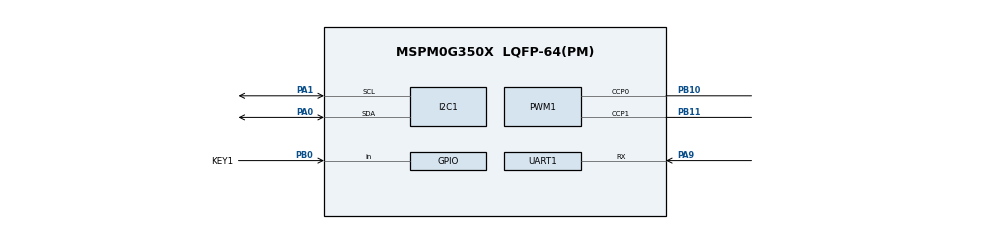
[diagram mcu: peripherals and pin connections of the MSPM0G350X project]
/**
 * @cliArgs --device "MSPM0G350X" --part "Default" --package "LQFP-64(PM)" --product "mspm0_sdk@2.04.00.06"
 * @versions {"tool":"1.21.1+3772"}
 */

/**
 * Import the modules used in this configuration.
 */
const GPIO   = scripting.addModule("/ti/driverlib/GPIO", {}, false);
const GPIO1  = GPIO.addInstance();
const GPIO2  = GPIO.addInstance();
const GPIO3  = GPIO.addInstance();
const GPIO4  = GPIO.addInstance();
const GPIO5  = GPIO.addInstance();
const GPIO6  = GPIO.addInstance();
const I2C    = scripting.addModule("/ti/driverlib/I2C", {}, false);
const I2C1   = I2C.addInstance();
const PWM    = scripting.addModule("/ti/driverlib/PWM", {}, false);
const PWM1   = PWM.addInstance();
const SYSCTL = scripting.addModule("/ti/driverlib/SYSCTL");
const TIMER  = scripting.addModule("/ti/driverlib/TIMER", {}, false);
const TIMER1 = TIMER.addInstance();
const UART   = scripting.addModule("/ti/driverlib/UART", {}, false);
const UART1  = UART.addInstance();

/**
 * Write custom configuration values to the imported modules.
 */
const divider7       = system.clockTree["PLL_PDIV"];
divider7.divideValue = 2;

const divider9       = system.clockTree["UDIV"];
divider9.divideValue = 2;

const multiplier2         = system.clockTree["PLL_QDIV"];
multiplier2.multiplyValue = 5;

const mux8       = system.clockTree["HSCLKMUX"];
mux8.inputSelect = "HSCLKMUX_SYSPLL2X";

GPIO1.$name                          = "TB";
GPIO1.associatedPins.create(4);
GPIO1.associatedPins[0].$name        = "AIN1";
GPIO1.associatedPins[0].assignedPort = "PORTB";
GPIO1.associatedPins[0].assignedPin  = "15";
GPIO1.associatedPins[1].$name        = "AIN2";
GPIO1.associatedPins[1].assignedPort = "PORTB";
GPIO1.associatedPins[1].assignedPin  = "13";
GPIO1.associatedPins[2].$name        = "BIN1";
GPIO1.associatedPins[2].assignedPort = "PORTB";
GPIO1.associatedPins[2].assignedPin  = "16";
GPIO1.associatedPins[3].$name        = "BIN2";
GPIO1.associatedPins[3].assignedPort = "PORTB";
GPIO1.associatedPins[3].assignedPin  = "12";

const Board = scripting.addModule("/ti/driverlib/Board", {}, false);

GPIO2.$name                          = "SG";
GPIO2.associatedPins.create(3);
GPIO2.associatedPins[0].$name        = "LED1";
GPIO2.associatedPins[0].assignedPort = "PORTB";
GPIO2.associatedPins[0].assignedPin  = "23";
GPIO2.associatedPins[1].$name        = "LED2";
GPIO2.associatedPins[1].assignedPin  = "21";
GPIO2.associatedPins[1].assignedPort = "PORTB";
GPIO2.associatedPins[2].$name        = "BUZZ";
GPIO2.associatedPins[2].assignedPort = "PORTB";
GPIO2.associatedPins[2].assignedPin  = "19";

GPIO3.$name                              = "KEY";
GPIO3.associatedPins.create(3);
GPIO3.associatedPins[0].$name            = "KEY2";
GPIO3.associatedPins[0].assignedPort     = "PORTB";
GPIO3.associatedPins[0].direction        = "INPUT";
GPIO3.associatedPins[0].internalResistor = "PULL_UP";
GPIO3.associatedPins[0].assignedPin      = "7";
GPIO3.associatedPins[1].$name            = "KEY3";
GPIO3.associatedPins[1].direction        = "INPUT";
GPIO3.associatedPins[1].internalResistor = "PULL_UP";
GPIO3.associatedPins[1].assignedPort     = "PORTB";
GPIO3.associatedPins[1].assignedPin      = "9";
GPIO3.associatedPins[2].$name            = "KEY1";
GPIO3.associatedPins[2].direction        = "INPUT";
GPIO3.associatedPins[2].internalResistor = "PULL_UP";
GPIO3.associatedPins[2].assignedPort     = "PORTB";
GPIO3.associatedPins[2].assignedPin      = "0";
GPIO3.associatedPins[2].pin.$assign      = "PB0";

GPIO4.$name                               = "EncoderA";
GPIO4.associatedPins.create(2);
GPIO4.associatedPins[0].$name             = "A_A";
GPIO4.associatedPins[0].direction         = "INPUT";
GPIO4.associatedPins[0].internalResistor  = "PULL_DOWN";
GPIO4.associatedPins[0].inputFilter       = "8_CYCLES";
GPIO4.associatedPins[0].interruptEn       = true;
GPIO4.associatedPins[0].interruptPriority = "0";
GPIO4.associatedPins[0].polarity          = "RISE";
GPIO4.associatedPins[0].assignedPort      = "PORTA";
GPIO4.associatedPins[0].assignedPin       = "26";
GPIO4.associatedPins[1].$name             = "A_B";
GPIO4.associatedPins[1].direction         = "INPUT";
GPIO4.associatedPins[1].internalResistor  = "PULL_DOWN";
GPIO4.associatedPins[1].inputFilter       = "8_CYCLES";
GPIO4.associatedPins[1].assignedPort      = "PORTA";
GPIO4.associatedPins[1].assignedPin       = "27";
GPIO4.associatedPins[1].interruptEn       = true;
GPIO4.associatedPins[1].interruptPriority = "0";
GPIO4.associatedPins[1].polarity          = "RISE";

GPIO5.$name                               = "EncoderB";
GPIO5.associatedPins.create(2);
GPIO5.associatedPins[0].direction         = "INPUT";
GPIO5.associatedPins[0].internalResistor  = "PULL_DOWN";
GPIO5.associatedPins[0].inputFilter       = "8_CYCLES";
GPIO5.associatedPins[0].interruptEn       = true;
GPIO5.associatedPins[0].interruptPriority = "0";
GPIO5.associatedPins[0].polarity          = "RISE";
GPIO5.associatedPins[0].$name             = "B_A";
GPIO5.associatedPins[0].assignedPort      = "PORTB";
GPIO5.associatedPins[0].assignedPin       = "6";
GPIO5.associatedPins[1].direction         = "INPUT";
GPIO5.associatedPins[1].internalResistor  = "PULL_DOWN";
GPIO5.associatedPins[1].inputFilter       = "8_CYCLES";
GPIO5.associatedPins[1].interruptEn       = true;
GPIO5.associatedPins[1].interruptPriority = "0";
GPIO5.associatedPins[1].polarity          = "RISE";
GPIO5.associatedPins[1].$name             = "B_B";
GPIO5.associatedPins[1].assignedPort      = "PORTB";
GPIO5.associatedPins[1].assignedPin       = "8";

GPIO6.$name                              = "XJ";
GPIO6.associatedPins.create(7);
GPIO6.associatedPins[0].$name            = "L3";
GPIO6.associatedPins[0].direction        = "INPUT";
GPIO6.associatedPins[0].internalResistor = "PULL_UP";
GPIO6.associatedPins[0].assignedPort     = "PORTA";
GPIO6.associatedPins[0].assignedPin      = "17";
GPIO6.associatedPins[1].$name            = "L2";
GPIO6.associatedPins[1].direction        = "INPUT";
GPIO6.associatedPins[1].internalResistor = "PULL_UP";
GPIO6.associatedPins[1].assignedPort     = "PORTA";
GPIO6.associatedPins[1].assignedPin      = "15";
GPIO6.associatedPins[2].$name            = "L1";
GPIO6.associatedPins[2].direction        = "INPUT";
GPIO6.associatedPins[2].assignedPort     = "PORTA";
GPIO6.associatedPins[2].assignedPin      = "16";
GPIO6.associatedPins[2].internalResistor = "PULL_UP";
GPIO6.associatedPins[3].$name            = "M";
GPIO6.associatedPins[3].direction        = "INPUT";
GPIO6.associatedPins[3].internalResistor = "PULL_UP";
GPIO6.associatedPins[3].assignedPort     = "PORTB";
GPIO6.associatedPins[3].assignedPin      = "18";
GPIO6.associatedPins[4].$name            = "R1";
GPIO6.associatedPins[4].direction        = "INPUT";
GPIO6.associatedPins[4].internalResistor = "PULL_UP";
GPIO6.associatedPins[4].assignedPort     = "PORTB";
GPIO6.associatedPins[4].assignedPin      = "20";
GPIO6.associatedPins[5].$name            = "R2";
GPIO6.associatedPins[5].direction        = "INPUT";
GPIO6.associatedPins[5].internalResistor = "PULL_UP";
GPIO6.associatedPins[5].assignedPort     = "PORTB";
GPIO6.associatedPins[5].assignedPin      = "24";
GPIO6.associatedPins[6].$name            = "R3";
GPIO6.associatedPins[6].direction        = "INPUT";
GPIO6.associatedPins[6].internalResistor = "PULL_UP";
GPIO6.associatedPins[6].assignedPort     = "PORTA";
GPIO6.associatedPins[6].assignedPin      = "24";

I2C1.$name                             = "I2C_OLED";
I2C1.basicEnableController             = true;
I2C1.basicControllerStandardBusSpeed   = "Fast";
I2C1.peripheral.$assign                = "I2C0";
I2C1.peripheral.sdaPin.$assign         = "PA0";
I2C1.peripheral.sclPin.$assign         = "PA1";
I2C1.sdaPinConfig.$name                = "ti_driverlib_gpio_GPIOPinGeneric0";
I2C1.sdaPinConfig.hideOutputInversion  = scripting.forceWrite(false);
I2C1.sdaPinConfig.onlyInternalResistor = scripting.forceWrite(false);
I2C1.sdaPinConfig.passedPeripheralType = scripting.forceWrite("Digital");
I2C1.sclPinConfig.hideOutputInversion  = scripting.forceWrite(false);
I2C1.sclPinConfig.onlyInternalResistor = scripting.forceWrite(false);
I2C1.sclPinConfig.passedPeripheralType = scripting.forceWrite("Digital");
I2C1.sclPinConfig.$name                = "ti_driverlib_gpio_GPIOPinGeneric2";

PWM1.$name                              = "TB_PWM";
PWM1.clockDivider                       = 4;
PWM1.pwmMode                            = "EDGE_ALIGN_UP";
PWM1.peripheral.$assign                 = "TIMG0";
PWM1.peripheral.ccp0Pin.$assign         = "PB10";
PWM1.peripheral.ccp1Pin.$assign         = "PB11";
PWM1.PWM_CHANNEL_0.$name                = "ti_driverlib_pwm_PWMTimerCC0";
PWM1.PWM_CHANNEL_1.$name                = "ti_driverlib_pwm_PWMTimerCC1";
PWM1.ccp0PinConfig.direction            = scripting.forceWrite("OUTPUT");
PWM1.ccp0PinConfig.hideOutputInversion  = scripting.forceWrite(false);
PWM1.ccp0PinConfig.onlyInternalResistor = scripting.forceWrite(false);
PWM1.ccp0PinConfig.passedPeripheralType = scripting.forceWrite("Digital");
PWM1.ccp0PinConfig.$name                = "ti_driverlib_gpio_GPIOPinGeneric3";
PWM1.ccp1PinConfig.direction            = scripting.forceWrite("OUTPUT");
PWM1.ccp1PinConfig.hideOutputInversion  = scripting.forceWrite(false);
PWM1.ccp1PinConfig.onlyInternalResistor = scripting.forceWrite(false);
PWM1.ccp1PinConfig.passedPeripheralType = scripting.forceWrite("Digital");
PWM1.ccp1PinConfig.$name                = "ti_driverlib_gpio_GPIOPinGeneric4";

SYSCTL.forceDefaultClkConfig = true;
SYSCTL.clockTreeEn           = true;
scripting.suppress("For best practices when the CPUCLK is running at 32MHz and above, clear the flash status bit using DL_FlashCTL_executeClearStatus\\(\\) before executing any flash operation\\. Otherwise there may be false positives\\.", SYSCTL);

TIMER1.timerClkPrescale   = 256;
TIMER1.timerMode          = "PERIODIC";
TIMER1.interrupts         = ["ZERO"];
TIMER1.$name              = "TIMER_Encoder_Read";
TIMER1.timerPeriod        = "5 ms";
TIMER1.peripheral.$assign = "TIMG6";

UART1.$name                            = "UART_WIT";
UART1.targetBaudRate                   = 115200;
UART1.direction                        = "RX";
UART1.enableFIFO                       = true;
UART1.rxTimeoutValue                   = 1;
UART1.enabledInterrupts                = ["RX_TIMEOUT_ERROR"];
UART1.enabledDMARXTriggers             = "DL_UART_DMA_INTERRUPT_RX";
UART1.peripheral.rxPin.$assign         = "PA9";
UART1.rxPinConfig.hideOutputInversion  = scripting.forceWrite(false);
UART1.rxPinConfig.onlyInternalResistor = scripting.forceWrite(false);
UART1.rxPinConfig.passedPeripheralType = scripting.forceWrite("Digital");
UART1.rxPinConfig.$name                = "ti_driverlib_gpio_GPIOPinGeneric1";
UART1.DMA_CHANNEL_RX.$name             = "DMA_WIT";
UART1.DMA_CHANNEL_RX.addressMode       = "f2b";
UART1.DMA_CHANNEL_RX.srcLength         = "BYTE";
UART1.DMA_CHANNEL_RX.dstLength         = "BYTE";

/**
 * Pinmux solution for unlocked pins/peripherals. This ensures that minor changes to the automatic solver in a future
 * version of the tool will not impact the pinmux you originally saw.  These lines can be completely deleted in order to
 * re-solve from scratch.
 */
GPIO1.associatedPins[0].pin.$suggestSolution     = "PB15";
GPIO1.associatedPins[1].pin.$suggestSolution     = "PB13";
GPIO1.associatedPins[2].pin.$suggestSolution     = "PB16";
GPIO1.associatedPins[3].pin.$suggestSolution     = "PB12";
Board.peripheral.$suggestSolution                = "DEBUGSS";
Board.peripheral.swclkPin.$suggestSolution       = "PA20";
Board.peripheral.swdioPin.$suggestSolution       = "PA19";
GPIO2.associatedPins[0].pin.$suggestSolution     = "PB23";
GPIO2.associatedPins[1].pin.$suggestSolution     = "PB21";
GPIO2.associatedPins[2].pin.$suggestSolution     = "PB19";
GPIO3.associatedPins[0].pin.$suggestSolution     = "PB7";
GPIO3.associatedPins[1].pin.$suggestSolution     = "PB9";
GPIO4.associatedPins[0].pin.$suggestSolution     = "PA26";
GPIO4.associatedPins[1].pin.$suggestSolution     = "PA27";
GPIO5.associatedPins[0].pin.$suggestSolution     = "PB6";
GPIO5.associatedPins[1].pin.$suggestSolution     = "PB8";
GPIO6.associatedPins[0].pin.$suggestSolution     = "PA17";
GPIO6.associatedPins[1].pin.$suggestSolution     = "PA15";
GPIO6.associatedPins[2].pin.$suggestSolution     = "PA16";
GPIO6.associatedPins[3].pin.$suggestSolution     = "PB18";
GPIO6.associatedPins[4].pin.$suggestSolution     = "PB20";
GPIO6.associatedPins[5].pin.$suggestSolution     = "PB24";
GPIO6.associatedPins[6].pin.$suggestSolution     = "PA24";
UART1.peripheral.$suggestSolution                = "UART1";
UART1.DMA_CHANNEL_RX.peripheral.$suggestSolution = "DMA_CH0";
